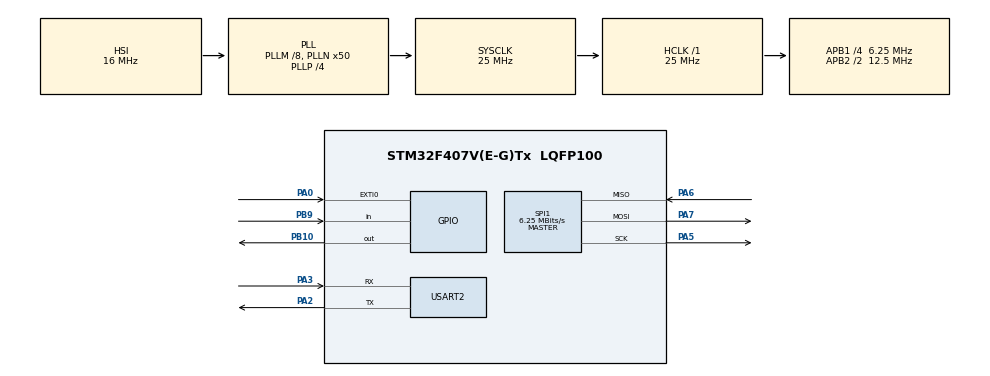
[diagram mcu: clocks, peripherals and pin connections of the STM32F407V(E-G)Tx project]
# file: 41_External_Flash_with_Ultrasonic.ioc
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Mcu.Family=STM32F4
Mcu.Name=STM32F407V(E-G)Tx
Mcu.Package=LQFP100
NVIC.EXTI0_IRQn=true\:0\:0\:false\:false\:true\:true\:true\:true
NVIC.PriorityGroup=NVIC_PRIORITYGROUP_0
PA0-WKUP.Signal=GPXTI0
PA13.Mode=Serial_Wire
PA13.Signal=SYS_JTMS-SWDIO
PA14.Mode=Serial_Wire
PA14.Signal=SYS_JTCK-SWCLK
PA2.Mode=Asynchronous
PA2.Signal=USART2_TX
PA3.Mode=Asynchronous
PA3.Signal=USART2_RX
PA5.Mode=Full_Duplex_Master
PA5.Signal=SPI1_SCK
PA6.Mode=Full_Duplex_Master
PA6.Signal=SPI1_MISO
PA7.Mode=Full_Duplex_Master
PA7.Signal=SPI1_MOSI
PB10.Signal=GPIO_Output
PB9.Signal=GPIO_Input
PH0-OSC_IN.Mode=HSE-External-Oscillator
PH0-OSC_IN.Signal=RCC_OSC_IN
PH1-OSC_OUT.Mode=HSE-External-Oscillator
PH1-OSC_OUT.Signal=RCC_OSC_OUT
ProjectManager.HeapSize=0x200
ProjectManager.StackSize=0x400
ProjectManager.TargetToolchain=STM32CubeIDE
RCC.48MHZClocksFreq_Value=14285714.285714285
RCC.AHBFreq_Value=25000000
RCC.APB1CLKDivider=RCC_HCLK_DIV4
RCC.APB1Freq_Value=6250000
RCC.APB1TimFreq_Value=12500000
RCC.APB2CLKDivider=RCC_HCLK_DIV2
RCC.APB2Freq_Value=12500000
RCC.APB2TimFreq_Value=25000000
RCC.CortexFreq_Value=25000000
RCC.HCLKFreq_Value=25000000
RCC.HSE_VALUE=8000000
RCC.HSI_VALUE=16000000
RCC.LSE_VALUE=32768
RCC.PLLM=8
RCC.PLLN=50
RCC.PLLP=RCC_PLLP_DIV4
RCC.PLLQ=7
RCC.SYSCLKFreq_VALUE=25000000
RCC.SYSCLKSource=RCC_SYSCLKSOURCE_PLLCLK
RCC.VCOOutputFreq_Value=100000000
SPI1.CalculateBaudRate=6.25 MBits/s
SPI1.Direction=SPI_DIRECTION_2LINES
SPI1.Mode=SPI_MODE_MASTER
SPI1.VirtualType=VM_MASTER
TIM3.Prescaler=24
USART2.VirtualMode=VM_ASYNC
VP_TIM3_VS_ClockSourceINT.Mode=Internal
board=STM32F407G-DISC1

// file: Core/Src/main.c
/* USER CODE BEGIN Header */
/**
  ******************************************************************************
  * @file           : main.c
  * @brief          : Main program body
  ******************************************************************************
  * @attention
  *
  * Copyright (c) 2026 STMicroelectronics.
  * All rights reserved.
  *
  * This software is licensed under terms that can be found in the LICENSE file
  * in the root directory of this software component.
  * If no LICENSE file comes with this software, it is provided AS-IS.
  *
  ******************************************************************************
  */
/* USER CODE END Header */
#include "main.h"

SPI_HandleTypeDef hspi1;

TIM_HandleTypeDef htim3;

UART_HandleTypeDef huart2;

void SystemClock_Config(void);
static void MX_GPIO_Init(void);
static void MX_SPI1_Init(void);
static void MX_USART2_UART_Init(void);
static void MX_TIM3_Init(void);

int interrupt_count = 0;
volatile uint8_t write_flag = 0;
int distance;
int main(void)
{

  /* MCU Configuration--------------------------------------------------------*/

  /* Reset of all peripherals, Initializes the Flash interface and the Systick. */
  HAL_Init();

  /* Configure the system clock */
  SystemClock_Config();

/* Initialize all configured peripherals */
  MX_USART2_UART_Init();
  MX_GPIO_Init();
  MX_SPI1_Init();
  MX_TIM3_Init();

  /* Infinite loop */
  while (1)
  {
	  distance = get_distance();

	 	  if(write_flag)
	 	  {
	 		  UART_Log("Entered\n\r");
	 	      write_flag = 0;

	 	      // Check if we have reached our limit (5 readings)
	 	      if(interrupt_count >= 5)
	 	      {
	 	          int32_t history[5];
	 	          char msg[100];
	 	          int len;

	 	          UART_Log("\r\n--- Reading History from External Flash ---\r\n");

	 	          for(int i = 0; i < 5; i++)
	 	          {
	 	              // Read 4 bytes (size of uint32_t) for each reading
	 	              W25_Read_Data(BASE_ADDRESS + (i * 4), (uint8_t*)&history[i], 4);

	 	              len = sprintf(msg, "Reading %d: %lu cm\r\n", i + 1, history[i]);
	 	              HAL_UART_Transmit(&huart2, (uint8_t*)msg, len, 100);
	 	          }

	 	          // Erase the sector before we start writing from the beginning again
	 	          UART_Log("Clearing External Flash Sector...\r\n");
	 	          W25_Erase_Sector(BASE_ADDRESS);

	 	          interrupt_count = 0;
	 	      }

	 	      // Calculate the byte address for the current 4-byte reading
	 	      uint32_t current_address = BASE_ADDRESS + (interrupt_count * 4);

	 	      // Write the distance (cast the pointer to uint8_t for the SPI function)
	 	      W25_Write_Page(current_address, (uint8_t*)&distance, 4);

	 	      interrupt_count++;
	 	  }

  }
}

  void UART_Log(char* msg) {
      HAL_UART_Transmit(&huart2, (uint8_t*)msg, strlen(msg), 100);
  }

  void W25_Wait_Busy(void) {
      uint8_t status = 0;
      uint8_t cmd = W25Q_READ_STATUS_REG1;
      do {
          W25_CS_SELECT();
          HAL_SPI_Transmit(&hspi1, &cmd, 1, 100);
          HAL_SPI_Receive(&hspi1, &status, 1, 100);
          W25_CS_DESELECT();
      } while ((status & 0x01) == 0x01); // Wait while BUSY bit is 1
  }

  void W25_Write_Enable(void) {
      uint8_t cmd = W25Q_WRITE_ENABLE;
      W25_CS_SELECT();
      HAL_SPI_Transmit(&hspi1, &cmd, 1, 100);
      W25_CS_DESELECT();
  }

  void W25_Write_Page(uint32_t address, uint8_t *pData, uint16_t size) {
      uint8_t cmd = W25Q_PAGE_PROGRAM;
      uint8_t addr_buf[3];

      // Convert 32-bit address to 3-byte SPI format
      addr_buf[0] = (address >> 16) & 0xFF;
      addr_buf[1] = (address >> 8) & 0xFF;
      addr_buf[2] = address & 0xFF;

      W25_Write_Enable(); // Must enable write latch first
      W25_CS_SELECT();

      HAL_SPI_Transmit(&hspi1, &cmd, 1, 100);      // Send Page Program Command
      HAL_SPI_Transmit(&hspi1, addr_buf, 3, 100);  // Send 24-bit Address
      HAL_SPI_Transmit(&hspi1, pData, size, 100);  // Send Data

      W25_CS_DESELECT();
      W25_Wait_Busy();    // Wait for the flash to finish internal write
  }

  void W25_Read_Data(uint32_t address, uint8_t *pBuffer, uint16_t size) {
      uint8_t cmd = W25Q_READ_DATA;
      uint8_t addr_buf[3];

      addr_buf[0] = (address >> 16) & 0xFF;
      addr_buf[1] = (address >> 8) & 0xFF;
      addr_buf[2] = address & 0xFF;

      W25_CS_SELECT();

      HAL_SPI_Transmit(&hspi1, &cmd, 1, 100);      // Send Read Command
      HAL_SPI_Transmit(&hspi1, addr_buf, 3, 100);  // Send 24-bit Address
      HAL_SPI_Receive(&hspi1, pBuffer, size, 500); // Receive Data

      W25_CS_DESELECT();
  }

  void W25_Erase_Sector(uint32_t address) {
      uint8_t cmd = W25Q_SECTOR_ERASE;
      uint8_t addr_buf[3];

      addr_buf[0] = (address >> 16) & 0xFF;
      addr_buf[1] = (address >> 8) & 0xFF;
      addr_buf[2] = address & 0xFF;

      W25_Write_Enable();
      W25_CS_SELECT();

      HAL_SPI_Transmit(&hspi1, &cmd, 1, 100);
      HAL_SPI_Transmit(&hspi1, addr_buf, 3, 100);

      W25_CS_DESELECT();
      W25_Wait_Busy(); // Erasing takes time (approx 40ms to 400ms)
  }

  void EXTI0_IRQHandler(void)
  {
      HAL_GPIO_EXTI_IRQHandler(GPIO_PIN_0);
  }
  void HAL_GPIO_EXTI_Callback(uint16_t GPIO_Pin)
  {
  	write_flag = 1;
  }

  void delay_us(uint16_t us)
  {
      __HAL_TIM_SET_COUNTER(&htim3, 0);
      while(__HAL_TIM_GET_COUNTER(&htim3) < us);
  }

  int get_distance(void)
  {
      uint32_t duration = 0;
      uint32_t timeout;

      //  Send TRIG pulse
      HAL_GPIO_WritePin(TRIG_PORT, TRIG_PIN, GPIO_PIN_RESET);
      delay_us(2);

      HAL_GPIO_WritePin(TRIG_PORT, TRIG_PIN, GPIO_PIN_SET);
      delay_us(10);

      HAL_GPIO_WritePin(TRIG_PORT, TRIG_PIN, GPIO_PIN_RESET);
      //  Wait for ECHO HIGH
      timeout = 30000;
      while(HAL_GPIO_ReadPin(ECHO_PORT, ECHO_PIN) == GPIO_PIN_RESET)
      {
    	  if(--timeout == 0) return -1;
      }

      //  Start timer
      __HAL_TIM_SET_COUNTER(&htim3, 0);

      // Wait for ECHO LOW
      timeout = 30000;
      while(HAL_GPIO_ReadPin(ECHO_PORT, ECHO_PIN) == GPIO_PIN_SET)
      {
          if(__HAL_TIM_GET_COUNTER(&htim3) > 30000) break;
      }
      //  Read duration
      duration = __HAL_TIM_GET_COUNTER(&htim3);

      //  Convert to distance
      distance = duration / 58;
      return distance;
  }

void SystemClock_Config(void)
{
  RCC_OscInitTypeDef RCC_OscInitStruct = {0};
  RCC_ClkInitTypeDef RCC_ClkInitStruct = {0};

  /** Configure the main internal regulator output voltage
  */
  __HAL_RCC_PWR_CLK_ENABLE();
  __HAL_PWR_VOLTAGESCALING_CONFIG(PWR_REGULATOR_VOLTAGE_SCALE1);

  /** Initializes the RCC Oscillators according to the specified parameters
  * in the RCC_OscInitTypeDef structure.
  */
  RCC_OscInitStruct.OscillatorType = RCC_OSCILLATORTYPE_HSI;
  RCC_OscInitStruct.HSIState = RCC_HSI_ON;
  RCC_OscInitStruct.HSICalibrationValue = RCC_HSICALIBRATION_DEFAULT;
  RCC_OscInitStruct.PLL.PLLState = RCC_PLL_ON;
  RCC_OscInitStruct.PLL.PLLSource = RCC_PLLSOURCE_HSI;
  RCC_OscInitStruct.PLL.PLLM = 8;
  RCC_OscInitStruct.PLL.PLLN = 50;
  RCC_OscInitStruct.PLL.PLLP = RCC_PLLP_DIV4;
  RCC_OscInitStruct.PLL.PLLQ = 7;
  if (HAL_RCC_OscConfig(&RCC_OscInitStruct) != HAL_OK)
  {
    Error_Handler();
  }

  /** Initializes the CPU, AHB and APB buses clocks
  */
  RCC_ClkInitStruct.ClockType = RCC_CLOCKTYPE_HCLK|RCC_CLOCKTYPE_SYSCLK
                              |RCC_CLOCKTYPE_PCLK1|RCC_CLOCKTYPE_PCLK2;
  RCC_ClkInitStruct.SYSCLKSource = RCC_SYSCLKSOURCE_PLLCLK;
  RCC_ClkInitStruct.AHBCLKDivider = RCC_SYSCLK_DIV1;
  RCC_ClkInitStruct.APB1CLKDivider = RCC_HCLK_DIV4;
  RCC_ClkInitStruct.APB2CLKDivider = RCC_HCLK_DIV2;

  if (HAL_RCC_ClockConfig(&RCC_ClkInitStruct, FLASH_LATENCY_0) != HAL_OK)
  {
    Error_Handler();
  }
}

static void MX_SPI1_Init(void)
{

  /* SPI1 parameter configuration*/
  hspi1.Instance = SPI1;
  hspi1.Init.Mode = SPI_MODE_MASTER;
  hspi1.Init.Direction = SPI_DIRECTION_2LINES;
  hspi1.Init.DataSize = SPI_DATASIZE_8BIT;
  hspi1.Init.CLKPolarity = SPI_POLARITY_LOW;
  hspi1.Init.CLKPhase = SPI_PHASE_1EDGE;
  hspi1.Init.NSS = SPI_NSS_SOFT;
  hspi1.Init.BaudRatePrescaler = SPI_BAUDRATEPRESCALER_16;
  hspi1.Init.FirstBit = SPI_FIRSTBIT_MSB;
  hspi1.Init.TIMode = SPI_TIMODE_DISABLE;
  hspi1.Init.CRCCalculation = SPI_CRCCALCULATION_DISABLE;
  hspi1.Init.CRCPolynomial = 10;
  if (HAL_SPI_Init(&hspi1) != HAL_OK)
  {
    Error_Handler();
  }
  UART_Log("SPI1 init Done\n\r");

}

static void MX_TIM3_Init(void)
{

  TIM_ClockConfigTypeDef sClockSourceConfig = {0};
  TIM_MasterConfigTypeDef sMasterConfig = {0};

  htim3.Instance = TIM3;
  htim3.Init.Prescaler = 16-1;
  htim3.Init.CounterMode = TIM_COUNTERMODE_UP;
  htim3.Init.Period = 65535;
  htim3.Init.ClockDivision = TIM_CLOCKDIVISION_DIV1;
  htim3.Init.AutoReloadPreload = TIM_AUTORELOAD_PRELOAD_DISABLE;

  if (HAL_TIM_Base_Init(&htim3) != HAL_OK)
  {
    Error_Handler();
  }
  sClockSourceConfig.ClockSource = TIM_CLOCKSOURCE_INTERNAL;
  if (HAL_TIM_ConfigClockSource(&htim3, &sClockSourceConfig) != HAL_OK)
  {
    Error_Handler();
  }
  sMasterConfig.MasterOutputTrigger = TIM_TRGO_RESET;
  sMasterConfig.MasterSlaveMode = TIM_MASTERSLAVEMODE_DISABLE;
  HAL_TIM_Base_Init(&htim3);
   HAL_TIM_Base_Start(&htim3);
  if (HAL_TIMEx_MasterConfigSynchronization(&htim3, &sMasterConfig) != HAL_OK)
  {
    Error_Handler();
  }
  UART_Log("TIM init Done\n\r");

}

static void MX_USART2_UART_Init(void)
{

  huart2.Instance = USART2;
  huart2.Init.BaudRate = 115200;
  huart2.Init.WordLength = UART_WORDLENGTH_8B;
  huart2.Init.StopBits = UART_STOPBITS_1;
  huart2.Init.Parity = UART_PARITY_NONE;
  huart2.Init.Mode = UART_MODE_TX_RX;
  huart2.Init.HwFlowCtl = UART_HWCONTROL_NONE;
  huart2.Init.OverSampling = UART_OVERSAMPLING_16;
  if (HAL_UART_Init(&huart2) != HAL_OK)
  {
    Error_Handler();
  }
  UART_Log("UART2 init Done\n\r");

}

static void MX_GPIO_Init(void)
{
  GPIO_InitTypeDef GPIO_InitStruct = {0};

  /* GPIO Ports Clock Enable */
  __HAL_RCC_GPIOA_CLK_ENABLE();
  __HAL_RCC_GPIOB_CLK_ENABLE();

  /*Configure GPIO pin Output Level */
  HAL_GPIO_WritePin(GPIOA, GPIO_PIN_4, GPIO_PIN_RESET);

  /*Configure GPIO pin Output Level */
  HAL_GPIO_WritePin(GPIOB, GPIO_PIN_10, GPIO_PIN_RESET);

  /*Configure GPIO pin : PA0 */
  GPIO_InitStruct.Pin = GPIO_PIN_0;
  GPIO_InitStruct.Mode = GPIO_MODE_IT_RISING;
  GPIO_InitStruct.Pull = GPIO_NOPULL;
  HAL_GPIO_Init(GPIOA, &GPIO_InitStruct);

  /*Configure GPIO pin : PA4 */
  GPIO_InitStruct.Pin = GPIO_PIN_4;
  GPIO_InitStruct.Mode = GPIO_MODE_OUTPUT_PP;
  GPIO_InitStruct.Pull = GPIO_NOPULL;
  GPIO_InitStruct.Speed = GPIO_SPEED_FREQ_VERY_HIGH;
  HAL_GPIO_Init(GPIOA, &GPIO_InitStruct);

  /*Configure GPIO pin : PB10 */
  GPIO_InitStruct.Pin = GPIO_PIN_10;
  GPIO_InitStruct.Mode = GPIO_MODE_OUTPUT_PP;
  GPIO_InitStruct.Pull = GPIO_NOPULL;
  GPIO_InitStruct.Speed = GPIO_SPEED_FREQ_LOW;
  HAL_GPIO_Init(GPIOB, &GPIO_InitStruct);

  /*Configure GPIO pin : PB9 */
  GPIO_InitStruct.Pin = GPIO_PIN_9;
  GPIO_InitStruct.Mode = GPIO_MODE_INPUT;
  GPIO_InitStruct.Pull = GPIO_NOPULL;
  HAL_GPIO_Init(GPIOB, &GPIO_InitStruct);

  /* USER CODE BEGIN MX_GPIO_Init_2 */
  HAL_NVIC_SetPriority(EXTI0_IRQn, 0, 0);
  HAL_NVIC_EnableIRQ(EXTI0_IRQn);

  UART_Log("GPIO init Done\n\r");

  /* USER CODE END MX_GPIO_Init_2 */
}

void Error_Handler(void)
{
  __disable_irq();
  while (1)
  {
  }
}
